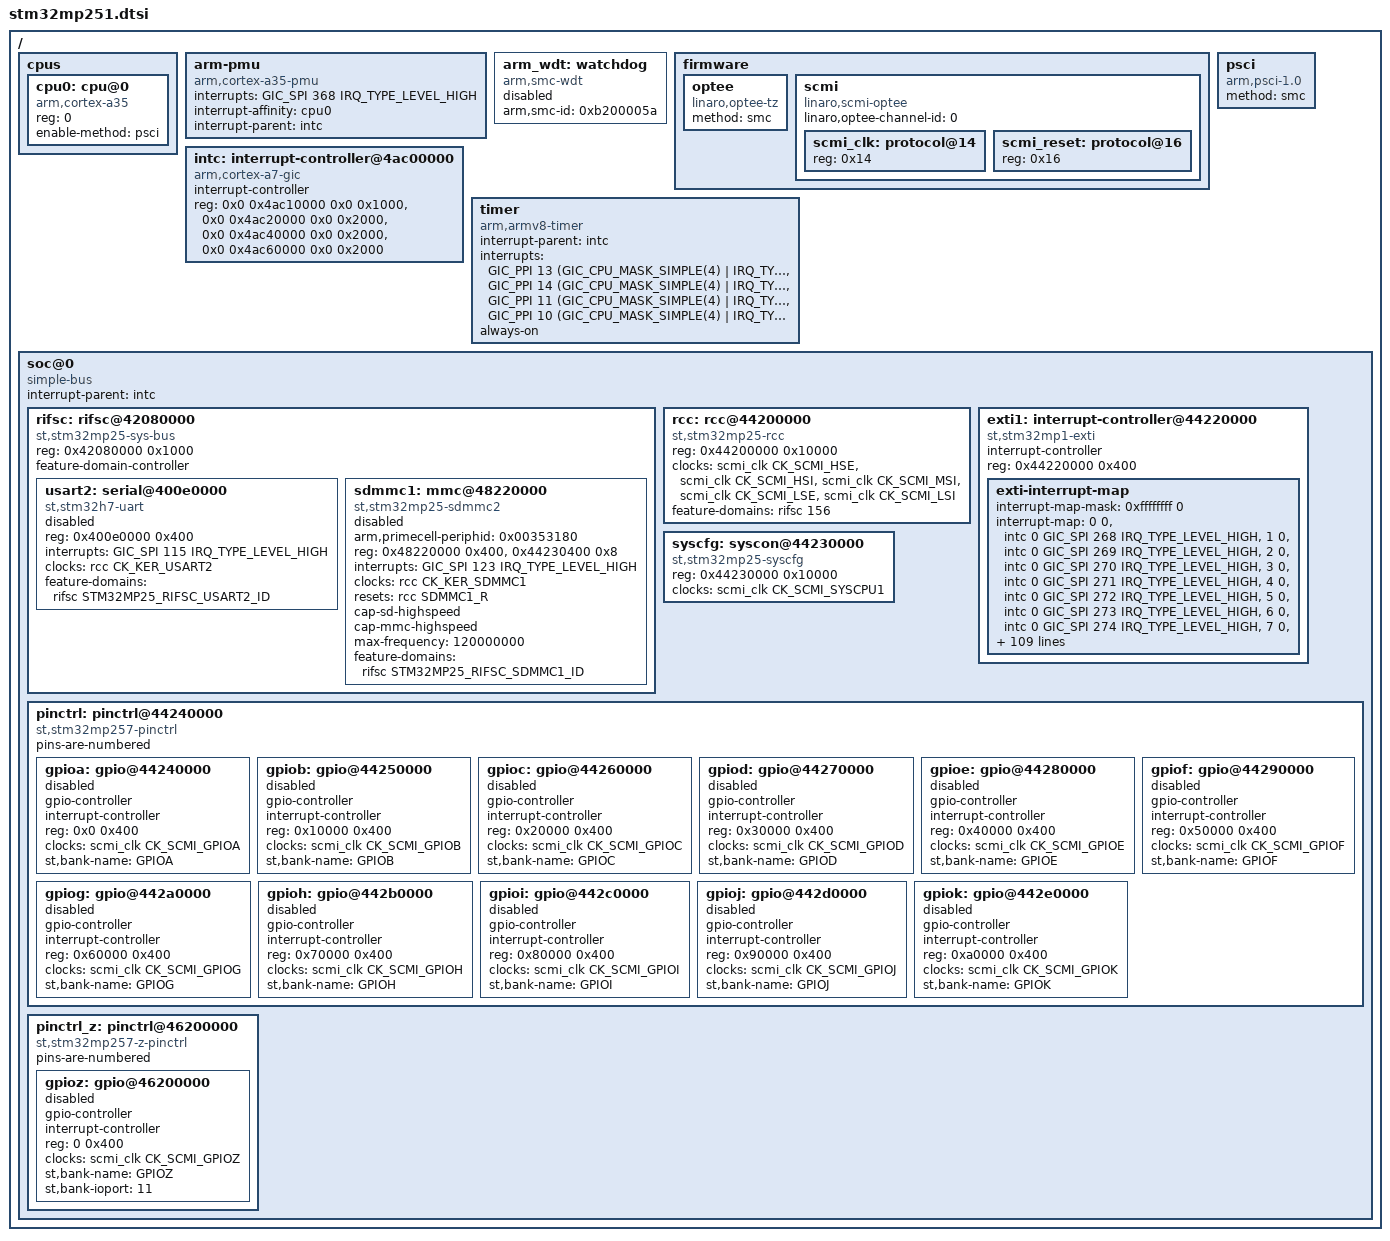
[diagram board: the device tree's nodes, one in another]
// SPDX-License-Identifier: (GPL-2.0-or-later OR BSD-3-Clause)
/*
 * Copyright (C) STMicroelectronics 2023 - All Rights Reserved
 * Author: Alexandre Torgue <alexandre.torgue@foss.st.com> for STMicroelectronics.
 */
#include <dt-bindings/bus/stm32mp25_sys_bus.h>
#include <dt-bindings/clock/stm32mp25-clks.h>
#include <dt-bindings/interrupt-controller/arm-gic.h>
#include <dt-bindings/reset/stm32mp25-resets.h>

/ {
	#address-cells = <2>;
	#size-cells = <2>;

	cpus {
		#address-cells = <1>;
		#size-cells = <0>;

		cpu0: cpu@0 {
			compatible = "arm,cortex-a35";
			device_type = "cpu";
			reg = <0>;
			enable-method = "psci";
		};
	};

	arm-pmu {
		compatible = "arm,cortex-a35-pmu";
		interrupts = <GIC_SPI 368 IRQ_TYPE_LEVEL_HIGH>;
		interrupt-affinity = <&cpu0>;
		interrupt-parent = <&intc>;
	};

	arm_wdt: watchdog {
		compatible = "arm,smc-wdt";
		arm,smc-id = <0xb200005a>;
		status = "disabled";
	};

	firmware {
		optee {
			compatible = "linaro,optee-tz";
			method = "smc";
		};

		scmi: scmi {
			compatible = "linaro,scmi-optee";
			#address-cells = <1>;
			#size-cells = <0>;
			linaro,optee-channel-id = <0>;

			scmi_clk: protocol@14 {
				reg = <0x14>;
				#clock-cells = <1>;
			};

			scmi_reset: protocol@16 {
				reg = <0x16>;
				#reset-cells = <1>;
			};
		};
	};

	intc: interrupt-controller@4ac00000 {
		compatible = "arm,cortex-a7-gic";
		#interrupt-cells = <3>;
		#address-cells = <1>;
		interrupt-controller;
		reg = <0x0 0x4ac10000 0x0 0x1000>,
		      <0x0 0x4ac20000 0x0 0x2000>,
		      <0x0 0x4ac40000 0x0 0x2000>,
		      <0x0 0x4ac60000 0x0 0x2000>;
	};

	psci {
		compatible = "arm,psci-1.0";
		method = "smc";
	};

	timer {
		compatible = "arm,armv8-timer";
		interrupt-parent = <&intc>;
		interrupts = <GIC_PPI 13 (GIC_CPU_MASK_SIMPLE(4) | IRQ_TYPE_LEVEL_LOW)>,
			     <GIC_PPI 14 (GIC_CPU_MASK_SIMPLE(4) | IRQ_TYPE_LEVEL_LOW)>,
			     <GIC_PPI 11 (GIC_CPU_MASK_SIMPLE(4) | IRQ_TYPE_LEVEL_LOW)>,
			     <GIC_PPI 10 (GIC_CPU_MASK_SIMPLE(4) | IRQ_TYPE_LEVEL_LOW)>;
		always-on;
	};

	soc@0 {
		compatible = "simple-bus";
		#address-cells = <1>;
		#size-cells = <1>;
		interrupt-parent = <&intc>;
		ranges = <0x0 0x0 0x0 0x80000000>;

		rifsc: rifsc@42080000 {
			compatible = "st,stm32mp25-sys-bus";
			reg = <0x42080000 0x1000>;
			#address-cells = <1>;
			#size-cells = <1>;
			ranges;
			feature-domain-controller;
			#feature-domain-cells = <1>;

			usart2: serial@400e0000 {
				compatible = "st,stm32h7-uart";
				reg = <0x400e0000 0x400>;
				interrupts = <GIC_SPI 115 IRQ_TYPE_LEVEL_HIGH>;
				clocks = <&rcc CK_KER_USART2>;
				feature-domains = <&rifsc STM32MP25_RIFSC_USART2_ID>;
				status = "disabled";
			};

			sdmmc1: mmc@48220000 {
				compatible = "st,stm32mp25-sdmmc2", "arm,pl18x", "arm,primecell";
				arm,primecell-periphid = <0x00353180>;
				reg = <0x48220000 0x400>, <0x44230400 0x8>;
				interrupts = <GIC_SPI 123 IRQ_TYPE_LEVEL_HIGH>;
				clocks = <&rcc CK_KER_SDMMC1>;
				clock-names = "apb_pclk";
				resets = <&rcc SDMMC1_R>;
				cap-sd-highspeed;
				cap-mmc-highspeed;
				max-frequency = <120000000>;
				feature-domains = <&rifsc STM32MP25_RIFSC_SDMMC1_ID>;
				status = "disabled";
			};
		};

		rcc: rcc@44200000 {
			compatible = "st,stm32mp25-rcc";
			reg = <0x44200000 0x10000>;
			#clock-cells = <1>;
			#reset-cells = <1>;
			clock-names = "hse", "hsi", "msi", "lse", "lsi";
			clocks = <&scmi_clk CK_SCMI_HSE>,
				<&scmi_clk CK_SCMI_HSI>,
				<&scmi_clk CK_SCMI_MSI>,
				<&scmi_clk CK_SCMI_LSE>,
				<&scmi_clk CK_SCMI_LSI>;
			feature-domains = <&rifsc 156>;
		};

		exti1: interrupt-controller@44220000 {
			compatible = "st,stm32mp1-exti", "syscon";
			interrupt-controller;
			#interrupt-cells = <2>;
			#address-cells = <0>;
			reg = <0x44220000 0x400>;

			exti-interrupt-map {
				#address-cells = <0>;
				#interrupt-cells = <2>;
				interrupt-map-mask = <0xffffffff 0>;
				interrupt-map =
					<0  0 &intc 0 GIC_SPI 268 IRQ_TYPE_LEVEL_HIGH>,
					<1  0 &intc 0 GIC_SPI 269 IRQ_TYPE_LEVEL_HIGH>,
					<2  0 &intc 0 GIC_SPI 270 IRQ_TYPE_LEVEL_HIGH>,
					<3  0 &intc 0 GIC_SPI 271 IRQ_TYPE_LEVEL_HIGH>,
					<4  0 &intc 0 GIC_SPI 272 IRQ_TYPE_LEVEL_HIGH>,
					<5  0 &intc 0 GIC_SPI 273 IRQ_TYPE_LEVEL_HIGH>,
					<6  0 &intc 0 GIC_SPI 274 IRQ_TYPE_LEVEL_HIGH>,
					<7  0 &intc 0 GIC_SPI 275 IRQ_TYPE_LEVEL_HIGH>,
					<8  0 &intc 0 GIC_SPI 276 IRQ_TYPE_LEVEL_HIGH>,
					<9  0 &intc 0 GIC_SPI 277 IRQ_TYPE_LEVEL_HIGH>,
					<10 0 &intc 0 GIC_SPI 278 IRQ_TYPE_LEVEL_HIGH>,
					<11 0 &intc 0 GIC_SPI 279 IRQ_TYPE_LEVEL_HIGH>,
					<12 0 &intc 0 GIC_SPI 280 IRQ_TYPE_LEVEL_HIGH>,
					<13 0 &intc 0 GIC_SPI 281 IRQ_TYPE_LEVEL_HIGH>,
					<14 0 &intc 0 GIC_SPI 282 IRQ_TYPE_LEVEL_HIGH>,
					<15 0 &intc 0 GIC_SPI 283 IRQ_TYPE_LEVEL_HIGH>,
					<16 0 &intc 0 GIC_SPI 0   IRQ_TYPE_LEVEL_HIGH>,
					<17 0 &intc 0 GIC_SPI 1   IRQ_TYPE_LEVEL_HIGH>,
					<18 0 &intc 0 GIC_SPI 260 IRQ_TYPE_LEVEL_HIGH>,
					<19 0 &intc 0 GIC_SPI 259 IRQ_TYPE_LEVEL_HIGH>,
					<21 0 &intc 0 GIC_SPI 108 IRQ_TYPE_LEVEL_HIGH>,
					<22 0 &intc 0 GIC_SPI 110 IRQ_TYPE_LEVEL_HIGH>,
					<23 0 &intc 0 GIC_SPI 137 IRQ_TYPE_LEVEL_HIGH>,
					<24 0 &intc 0 GIC_SPI 168 IRQ_TYPE_LEVEL_HIGH>,
					<25 0 &intc 0 GIC_SPI 181 IRQ_TYPE_LEVEL_HIGH>,
					<26 0 &intc 0 GIC_SPI 114 IRQ_TYPE_LEVEL_HIGH>,
					<27 0 &intc 0 GIC_SPI 115 IRQ_TYPE_LEVEL_HIGH>,
					<28 0 &intc 0 GIC_SPI 116 IRQ_TYPE_LEVEL_HIGH>,
					<29 0 &intc 0 GIC_SPI 136 IRQ_TYPE_LEVEL_HIGH>,
					<30 0 &intc 0 GIC_SPI 126 IRQ_TYPE_LEVEL_HIGH>,
					<31 0 &intc 0 GIC_SPI 127 IRQ_TYPE_LEVEL_HIGH>,
					<32 0 &intc 0 GIC_SPI 148 IRQ_TYPE_LEVEL_HIGH>,
					<33 0 &intc 0 GIC_SPI 149 IRQ_TYPE_LEVEL_HIGH>,
					<34 0 &intc 0 GIC_SPI 150 IRQ_TYPE_LEVEL_HIGH>,
					<36 0 &intc 0 GIC_SPI 112 IRQ_TYPE_LEVEL_HIGH>,
					<37 0 &intc 0 GIC_SPI 113 IRQ_TYPE_LEVEL_HIGH>,
					<38 0 &intc 0 GIC_SPI 125 IRQ_TYPE_LEVEL_HIGH>,
					<39 0 &intc 0 GIC_SPI 152 IRQ_TYPE_LEVEL_HIGH>,
					<40 0 &intc 0 GIC_SPI 153 IRQ_TYPE_LEVEL_HIGH>,
					<41 0 &intc 0 GIC_SPI 154 IRQ_TYPE_LEVEL_HIGH>,
					<42 0 &intc 0 GIC_SPI 155 IRQ_TYPE_LEVEL_HIGH>,
					<43 0 &intc 0 GIC_SPI 169 IRQ_TYPE_LEVEL_HIGH>,
					<44 0 &intc 0 GIC_SPI 182 IRQ_TYPE_LEVEL_HIGH>,
					<45 0 &intc 0 GIC_SPI 209 IRQ_TYPE_LEVEL_HIGH>,
					<46 0 &intc 0 GIC_SPI 229 IRQ_TYPE_LEVEL_HIGH>,
					<47 0 &intc 0 GIC_SPI 166 IRQ_TYPE_LEVEL_HIGH>,
					<48 0 &intc 0 GIC_SPI 215 IRQ_TYPE_LEVEL_HIGH>,
					<49 0 &intc 0 GIC_SPI 208 IRQ_TYPE_LEVEL_HIGH>,
					<50 0 &intc 0 GIC_SPI 210 IRQ_TYPE_LEVEL_HIGH>,
					<59 0 &intc 0 GIC_SPI 171 IRQ_TYPE_LEVEL_HIGH>,
					//	<59 0 &intc 0 GIC_SPI 172 IRQ_TYPE_LEVEL_HIGH>,
					<61 0 &intc 0 GIC_SPI 173 IRQ_TYPE_LEVEL_HIGH>,
					//	<61 0 &intc 0 GIC_SPI 174 IRQ_TYPE_LEVEL_HIGH>,
					<64 0 &intc 0 GIC_SPI 220 IRQ_TYPE_LEVEL_HIGH>,
					<67 0 &intc 0 GIC_SPI 10  IRQ_TYPE_LEVEL_HIGH>,
					<68 0 &intc 0 GIC_SPI 131 IRQ_TYPE_LEVEL_HIGH>,
					<70 0 &intc 0 GIC_SPI 134 IRQ_TYPE_LEVEL_HIGH>,
					<72 0 &intc 0 GIC_SPI 224 IRQ_TYPE_LEVEL_HIGH>,
					<73 0 &intc 0 GIC_SPI 202 IRQ_TYPE_LEVEL_HIGH>,
					<74 0 &intc 0 GIC_SPI 109 IRQ_TYPE_LEVEL_HIGH>,
					<75 0 &intc 0 GIC_SPI 111 IRQ_TYPE_LEVEL_HIGH>,
					<76 0 &intc 0 GIC_SPI 138 IRQ_TYPE_LEVEL_HIGH>,
					<77 0 &intc 0 GIC_SPI 253 IRQ_TYPE_LEVEL_HIGH>,
					<78 0 &intc 0 GIC_SPI 254 IRQ_TYPE_LEVEL_HIGH>,
					<79 0 &intc 0 GIC_SPI 255 IRQ_TYPE_LEVEL_HIGH>,
					<83 0 &intc 0 GIC_SPI 257 IRQ_TYPE_LEVEL_HIGH>,
					<84 0 &intc 0 GIC_SPI 258 IRQ_TYPE_LEVEL_HIGH>;
			};
		};

		syscfg: syscon@44230000 {
			compatible = "st,stm32mp25-syscfg", "syscon";
			reg = <0x44230000 0x10000>;
			clocks = <&scmi_clk CK_SCMI_SYSCPU1>;
		};

		/* Break node order to solve dependency probe issue between pinctrl and exti. */

		pinctrl: pinctrl@44240000 {
			#address-cells = <1>;
			#size-cells = <1>;
			compatible = "st,stm32mp257-pinctrl";
			ranges = <0 0x44240000 0xa0400>;
			pins-are-numbered;

			gpioa: gpio@44240000 {
				gpio-controller;
				#gpio-cells = <2>;
				interrupt-controller;
				#interrupt-cells = <2>;
				reg = <0x0 0x400>;
				clocks = <&scmi_clk CK_SCMI_GPIOA>;
				st,bank-name = "GPIOA";
				status = "disabled";
			};

			gpiob: gpio@44250000 {
				gpio-controller;
				#gpio-cells = <2>;
				interrupt-controller;
				#interrupt-cells = <2>;
				reg = <0x10000 0x400>;
				clocks = <&scmi_clk CK_SCMI_GPIOB>;
				st,bank-name = "GPIOB";
				status = "disabled";
			};

			gpioc: gpio@44260000 {
				gpio-controller;
				#gpio-cells = <2>;
				interrupt-controller;
				#interrupt-cells = <2>;
				reg = <0x20000 0x400>;
				clocks = <&scmi_clk CK_SCMI_GPIOC>;
				st,bank-name = "GPIOC";
				status = "disabled";
			};

			gpiod: gpio@44270000 {
				gpio-controller;
				#gpio-cells = <2>;
				interrupt-controller;
				#interrupt-cells = <2>;
				reg = <0x30000 0x400>;
				clocks = <&scmi_clk CK_SCMI_GPIOD>;
				st,bank-name = "GPIOD";
				status = "disabled";
			};

			gpioe: gpio@44280000 {
				gpio-controller;
				#gpio-cells = <2>;
				interrupt-controller;
				#interrupt-cells = <2>;
				reg = <0x40000 0x400>;
				clocks = <&scmi_clk CK_SCMI_GPIOE>;
				st,bank-name = "GPIOE";
				status = "disabled";
			};

			gpiof: gpio@44290000 {
				gpio-controller;
				#gpio-cells = <2>;
				interrupt-controller;
				#interrupt-cells = <2>;
				reg = <0x50000 0x400>;
				clocks = <&scmi_clk CK_SCMI_GPIOF>;
				st,bank-name = "GPIOF";
				status = "disabled";
			};

			gpiog: gpio@442a0000 {
				gpio-controller;
				#gpio-cells = <2>;
				interrupt-controller;
				#interrupt-cells = <2>;
				reg = <0x60000 0x400>;
				clocks = <&scmi_clk CK_SCMI_GPIOG>;
				st,bank-name = "GPIOG";
				status = "disabled";
			};

			gpioh: gpio@442b0000 {
				gpio-controller;
				#gpio-cells = <2>;
				interrupt-controller;
				#interrupt-cells = <2>;
				reg = <0x70000 0x400>;
				clocks = <&scmi_clk CK_SCMI_GPIOH>;
				st,bank-name = "GPIOH";
				status = "disabled";
			};

			gpioi: gpio@442c0000 {
				gpio-controller;
				#gpio-cells = <2>;
				interrupt-controller;
				#interrupt-cells = <2>;
				reg = <0x80000 0x400>;
				clocks = <&scmi_clk CK_SCMI_GPIOI>;
				st,bank-name = "GPIOI";
				status = "disabled";
			};

			gpioj: gpio@442d0000 {
				gpio-controller;
				#gpio-cells = <2>;
				interrupt-controller;
				#interrupt-cells = <2>;
				reg = <0x90000 0x400>;
				clocks = <&scmi_clk CK_SCMI_GPIOJ>;
				st,bank-name = "GPIOJ";
				status = "disabled";
			};

			gpiok: gpio@442e0000 {
				gpio-controller;
				#gpio-cells = <2>;
				interrupt-controller;
				#interrupt-cells = <2>;
				reg = <0xa0000 0x400>;
				clocks = <&scmi_clk CK_SCMI_GPIOK>;
				st,bank-name = "GPIOK";
				status = "disabled";
			};
		};

		pinctrl_z: pinctrl@46200000 {
			#address-cells = <1>;
			#size-cells = <1>;
			compatible = "st,stm32mp257-z-pinctrl";
			ranges = <0 0x46200000 0x400>;
			pins-are-numbered;

			gpioz: gpio@46200000 {
				gpio-controller;
				#gpio-cells = <2>;
				interrupt-controller;
				#interrupt-cells = <2>;
				reg = <0 0x400>;
				clocks = <&scmi_clk CK_SCMI_GPIOZ>;
				st,bank-name = "GPIOZ";
				st,bank-ioport = <11>;
				status = "disabled";
			};

		};
	};
};
